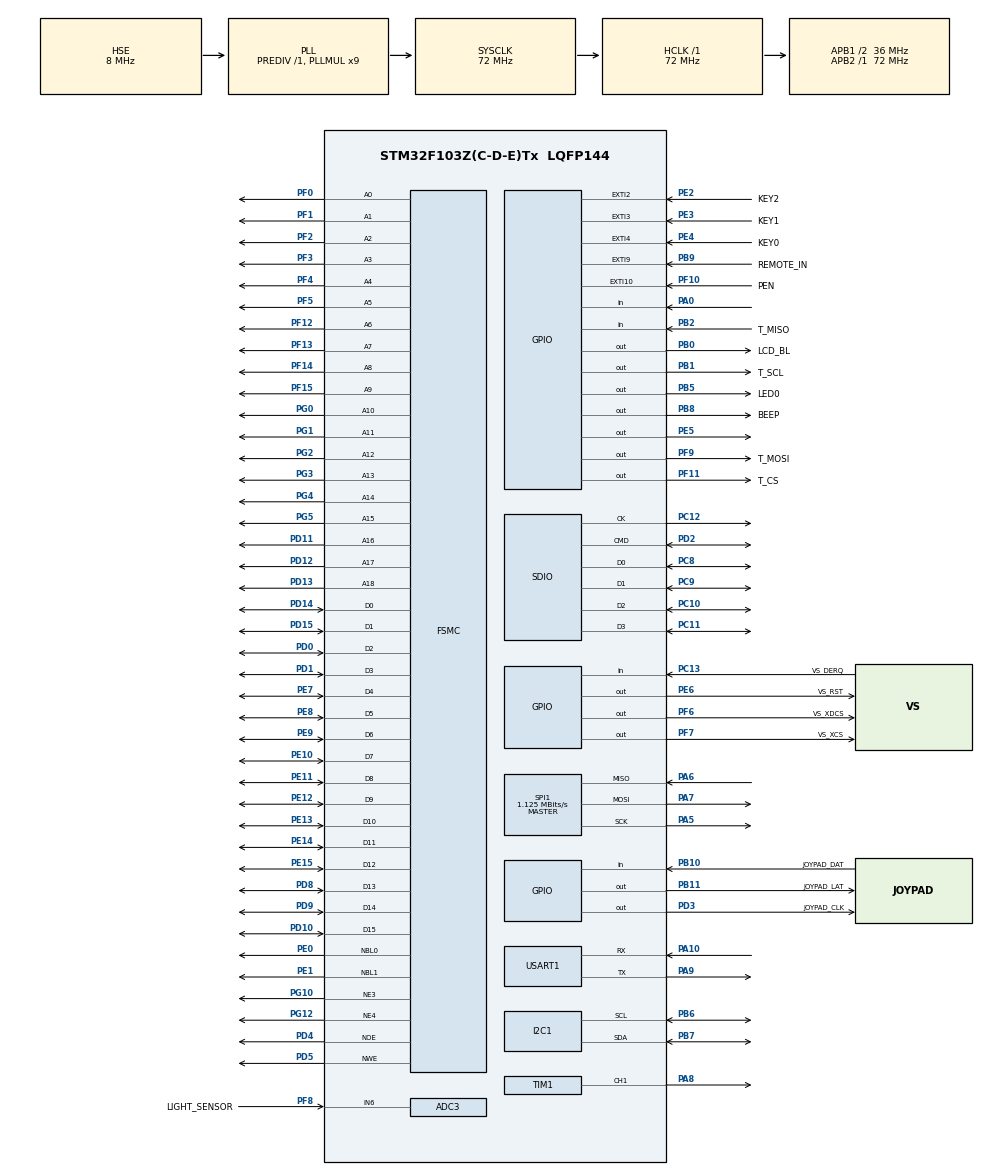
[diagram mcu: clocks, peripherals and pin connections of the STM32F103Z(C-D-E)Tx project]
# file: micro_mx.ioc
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ADC1.Channel-0\#ChannelRegularConversion=ADC_CHANNEL_TEMPSENSOR
ADC1.ContinuousConvMode=ENABLE
ADC1.NbrOfConversionFlag=1
ADC1.Rank-0\#ChannelRegularConversion=1
ADC1.SamplingTime-0\#ChannelRegularConversion=ADC_SAMPLETIME_1CYCLE_5
ADC1.master=1
ADC3.Channel-2\#ChannelRegularConversion=ADC_CHANNEL_6
ADC3.ContinuousConvMode=ENABLE
ADC3.NbrOfConversionFlag=1
ADC3.Rank-2\#ChannelRegularConversion=1
ADC3.SamplingTime-2\#ChannelRegularConversion=ADC_SAMPLETIME_1CYCLE_5
Dma.Request0=SDIO
Dma.SDIO.0.Direction=DMA_PERIPH_TO_MEMORY
Dma.SDIO.0.Instance=DMA2_Channel4
Dma.SDIO.0.MemDataAlignment=DMA_MDATAALIGN_WORD
Dma.SDIO.0.MemInc=DMA_MINC_ENABLE
Dma.SDIO.0.Mode=DMA_NORMAL
Dma.SDIO.0.PeriphDataAlignment=DMA_PDATAALIGN_WORD
Dma.SDIO.0.PeriphInc=DMA_PINC_DISABLE
Dma.SDIO.0.Priority=DMA_PRIORITY_LOW
FATFS.BSP.number=1
FATFS._FS_TINY=0
FATFS0.BSP.STBoard=false
FATFS0.BSP.api=Unknown
FATFS0.BSP.i2caddr=0
FATFS0.BSP.instance=PA0-WKUP
FATFS0.BSP.ip=GPIO
FATFS0.BSP.mode=Input
FATFS0.BSP.name=Detect_SDIO
FATFS0.BSP.solution=PA0-WKUP
FSMC.AddressSetupTime1=6
FSMC.AddressSetupTime2=4
FSMC.BusTurnAroundDuration1=0
FSMC.BusTurnAroundDuration2=0
FSMC.DataSetupTime1=26
FSMC.DataSetupTime2=4
FSMC.WriteOperation2=FSMC_WRITE_OPERATION_ENABLE
I2C1.I2C_Mode=I2C_Standard
Mcu.Family=STM32F1
Mcu.Name=STM32F103Z(C-D-E)Tx
Mcu.Package=LQFP144
NVIC.DMA2_Channel4_5_IRQn=true\:0\:0\:false\:false\:true\:false\:true\:true
NVIC.EXTI15_10_IRQn=true\:0\:0\:false\:false\:true\:true\:true\:true
NVIC.EXTI2_IRQn=true\:3\:0\:true\:false\:true\:true\:true\:true
NVIC.EXTI3_IRQn=true\:3\:0\:true\:false\:true\:true\:true\:true
NVIC.EXTI4_IRQn=true\:3\:0\:true\:false\:true\:true\:true\:true
NVIC.EXTI9_5_IRQn=true\:0\:0\:false\:false\:true\:true\:true\:true
NVIC.PriorityGroup=NVIC_PRIORITYGROUP_4
NVIC.SDIO_IRQn=true\:0\:0\:false\:false\:true\:true\:true\:true
NVIC.TIM2_IRQn=true\:0\:0\:false\:false\:true\:true\:true\:true
NVIC.USART1_IRQn=true\:0\:0\:false\:false\:true\:true\:true\:true
OSC_IN.Mode=HSE-External-Oscillator
OSC_IN.Signal=RCC_OSC_IN
OSC_OUT.Mode=HSE-External-Oscillator
OSC_OUT.Signal=RCC_OSC_OUT
PA0-WKUP.GPIO_PuPd=GPIO_PULLUP
PA0-WKUP.Signal=GPIO_Input
PA10.Mode=Asynchronous
PA10.Signal=USART1_RX
PA13.Mode=JTAG_5_pins
PA13.Signal=SYS_JTMS-SWDIO
PA14.Mode=JTAG_5_pins
PA14.Signal=SYS_JTCK-SWCLK
PA15.Mode=JTAG_5_pins
PA15.Signal=SYS_JTDI
PA5.Mode=Full_Duplex_Master
PA5.Signal=SPI1_SCK
PA6.Mode=Full_Duplex_Master
PA6.Signal=SPI1_MISO
PA7.Mode=Full_Duplex_Master
PA7.Signal=SPI1_MOSI
PA8.Signal=S_TIM1_CH1
PA9.Mode=Asynchronous
PA9.Signal=USART1_TX
PB0.GPIO_Label=LCD_BL
PB0.Signal=GPIO_Output
PB1.GPIO_Label=T_SCL
PB1.Signal=GPIO_Output
PB10.GPIO_Label=JOYPAD_DAT
PB10.Signal=GPIO_Input
PB11.GPIO_Label=JOYPAD_LAT
PB11.Signal=GPIO_Output
PB2.GPIO_Label=T_MISO
PB2.Signal=GPIO_Input
PB3.Mode=JTAG_5_pins
PB3.Signal=SYS_JTDO-TRACESWO
PB4.Mode=JTAG_5_pins
PB4.Signal=SYS_NJTRST
PB5.GPIO_Label=LED0
PB5.PinState=GPIO_PIN_SET
PB5.Signal=GPIO_Output
PB6.GPIO_Pu=GPIO_PULLUP
PB6.Mode=I2C
PB6.Signal=I2C1_SCL
PB7.GPIO_Pu=GPIO_PULLUP
PB7.Mode=I2C
PB7.Signal=I2C1_SDA
PB8.GPIO_Label=BEEP
PB8.Signal=GPIO_Output
PB9.GPIO_Label=REMOTE_IN
PB9.GPIO_ModeDefaultEXTI=GPIO_MODE_IT_FALLING
PB9.Signal=GPXTI9
PC10.Mode=SD_4_bits_Wide_bus
PC10.Signal=SDIO_D2
PC11.Mode=SD_4_bits_Wide_bus
PC11.Signal=SDIO_D3
PC12.Mode=SD_4_bits_Wide_bus
PC12.Signal=SDIO_CK
PC13-TAMPER-RTC.GPIO_Label=VS_DERQ
PC13-TAMPER-RTC.Signal=GPIO_Input
PC14-OSC32_IN.Mode=LSE-External-Oscillator
PC14-OSC32_IN.Signal=RCC_OSC32_IN
PC15-OSC32_OUT.Mode=LSE-External-Oscillator
PC15-OSC32_OUT.Signal=RCC_OSC32_OUT
PC8.Mode=SD_4_bits_Wide_bus
PC8.Signal=SDIO_D0
PC9.Mode=SD_4_bits_Wide_bus
PC9.Signal=SDIO_D1
PD0.Signal=FSMC_D2_DA2
PD1.Signal=FSMC_D3_DA3
PD10.Signal=FSMC_D15_DA15
PD11.Signal=FSMC_A16_CLE
PD12.Signal=FSMC_A17_ALE
PD13.Signal=FSMC_A18
PD14.Signal=FSMC_D0_DA0
PD15.Signal=FSMC_D1_DA1
PD2.Mode=SD_4_bits_Wide_bus
PD2.Signal=SDIO_CMD
PD3.GPIO_Label=JOYPAD_CLK
PD3.Signal=GPIO_Output
PD4.Signal=FSMC_NOE
PD5.Signal=FSMC_NWE
PD8.Signal=FSMC_D13_DA13
PD9.Signal=FSMC_D14_DA14
PE0.Signal=FSMC_NBL0
PE1.Signal=FSMC_NBL1
PE10.Signal=FSMC_D7_DA7
PE11.Signal=FSMC_D8_DA8
PE12.Signal=FSMC_D9_DA9
PE13.Signal=FSMC_D10_DA10
PE14.Signal=FSMC_D11_DA11
PE15.Signal=FSMC_D12_DA12
PE2.GPIO_Label=KEY2
PE2.GPIO_ModeDefaultEXTI=GPIO_MODE_IT_FALLING
PE2.GPIO_PuPd=GPIO_PULLUP
PE2.Signal=GPXTI2
PE3.GPIO_Label=KEY1
PE3.GPIO_ModeDefaultEXTI=GPIO_MODE_IT_FALLING
PE3.GPIO_PuPd=GPIO_PULLUP
PE3.Signal=GPXTI3
PE4.GPIO_Label=KEY0
PE4.GPIO_ModeDefaultEXTI=GPIO_MODE_IT_FALLING
PE4.GPIO_PuPd=GPIO_PULLUP
PE4.Signal=GPXTI4
PE5.Signal=GPIO_Output
PE6.GPIO_Label=VS_RST
PE6.Signal=GPIO_Output
PE7.Signal=FSMC_D4_DA4
PE8.Signal=FSMC_D5_DA5
PE9.Signal=FSMC_D6_DA6
PF0.Signal=FSMC_A0
PF1.Signal=FSMC_A1
PF10.GPIO_Label=PEN
PF10.GPIO_ModeDefaultEXTI=GPIO_MODE_IT_FALLING
PF10.Signal=GPXTI10
PF11.GPIO_Label=T_CS
PF11.PinState=GPIO_PIN_SET
PF11.Signal=GPIO_Output
PF12.Signal=FSMC_A6
PF13.Signal=FSMC_A7
PF14.Signal=FSMC_A8
PF15.Signal=FSMC_A9
PF2.Signal=FSMC_A2
PF3.Signal=FSMC_A3
PF4.Signal=FSMC_A4
PF5.Signal=FSMC_A5
PF6.GPIO_Label=VS_XDCS
PF6.Signal=GPIO_Output
PF7.GPIO_Label=VS_XCS
PF7.PinState=GPIO_PIN_SET
PF7.Signal=GPIO_Output
PF8.GPIO_Label=LIGHT_SENSOR
PF8.Signal=SharedAnalog_PF8
PF9.GPIO_Label=T_MOSI
PF9.Signal=GPIO_Output
PG0.Signal=FSMC_A10
PG1.Signal=FSMC_A11
PG10.Mode=NorPsramChipSelect3_2
PG10.Signal=FSMC_NE3
PG12.Mode=NorPsramChipSelect4_1
PG12.Signal=FSMC_NE4
PG2.Signal=FSMC_A12
PG3.Signal=FSMC_A13
PG4.Signal=FSMC_A14
PG5.Signal=FSMC_A15
ProjectManager.HeapSize=0x400
ProjectManager.StackSize=0x800
ProjectManager.TargetToolchain=STM32CubeIDE
RCC.ADCPresc=RCC_ADCPCLK2_DIV6
RCC.AHBFreq_Value=72000000
RCC.APB1CLKDivider=RCC_HCLK_DIV2
RCC.APB1Freq_Value=36000000
RCC.APB1TimFreq_Value=72000000
RCC.APB2Freq_Value=72000000
RCC.APB2TimFreq_Value=72000000
RCC.HCLKFreq_Value=72000000
RCC.PLLMUL=RCC_PLL_MUL9
RCC.PLLSourceVirtual=RCC_PLLSOURCE_HSE
RCC.RTCClockSelection=RCC_RTCCLKSOURCE_LSE
RCC.SYSCLKFreq_VALUE=72000000
RCC.SYSCLKSource=RCC_SYSCLKSOURCE_PLLCLK
RCC.USBFreq_Value=48000000
RCC.USBPrescaler=RCC_USBCLKSOURCE_PLL_DIV1_5
SDIO.ClockBypass=SDIO_CLOCK_BYPASS_DISABLE
SDIO.ClockDiv=10
SDIO.HardwareFlowControl=SDIO_HARDWARE_FLOW_CONTROL_DISABLE
SH.FSMC_A0.0=FSMC_A0,19b-a2
SH.FSMC_A1.0=FSMC_A1,19b-a2
SH.FSMC_A10.0=FSMC_A10,A10_1
SH.FSMC_A10.1=FSMC_A10,19b-a2
SH.FSMC_A11.0=FSMC_A11,19b-a2
SH.FSMC_A12.0=FSMC_A12,19b-a2
SH.FSMC_A13.0=FSMC_A13,19b-a2
SH.FSMC_A14.0=FSMC_A14,19b-a2
SH.FSMC_A15.0=FSMC_A15,19b-a2
SH.FSMC_A16_CLE.0=FSMC_A16,19b-a2
SH.FSMC_A17_ALE.0=FSMC_A17,19b-a2
SH.FSMC_A18.0=FSMC_A18,19b-a2
SH.FSMC_A2.0=FSMC_A2,19b-a2
SH.FSMC_A3.0=FSMC_A3,19b-a2
SH.FSMC_A4.0=FSMC_A4,19b-a2
SH.FSMC_A5.0=FSMC_A5,19b-a2
SH.FSMC_A6.0=FSMC_A6,19b-a2
SH.FSMC_A7.0=FSMC_A7,19b-a2
SH.FSMC_A8.0=FSMC_A8,19b-a2
SH.FSMC_A9.0=FSMC_A9,19b-a2
SH.FSMC_D0_DA0.0=FSMC_D0,16b-d1
SH.FSMC_D0_DA0.1=FSMC_D0,16b-d2
SH.FSMC_D10_DA10.0=FSMC_D10,16b-d1
SH.FSMC_D10_DA10.1=FSMC_D10,16b-d2
SH.FSMC_D11_DA11.0=FSMC_D11,16b-d1
SH.FSMC_D11_DA11.1=FSMC_D11,16b-d2
SH.FSMC_D12_DA12.0=FSMC_D12,16b-d1
SH.FSMC_D12_DA12.1=FSMC_D12,16b-d2
SH.FSMC_D13_DA13.0=FSMC_D13,16b-d1
SH.FSMC_D13_DA13.1=FSMC_D13,16b-d2
SH.FSMC_D14_DA14.0=FSMC_D14,16b-d1
SH.FSMC_D14_DA14.1=FSMC_D14,16b-d2
SH.FSMC_D15_DA15.0=FSMC_D15,16b-d1
SH.FSMC_D15_DA15.1=FSMC_D15,16b-d2
SH.FSMC_D1_DA1.0=FSMC_D1,16b-d1
SH.FSMC_D1_DA1.1=FSMC_D1,16b-d2
SH.FSMC_D2_DA2.0=FSMC_D2,16b-d1
SH.FSMC_D2_DA2.1=FSMC_D2,16b-d2
SH.FSMC_D3_DA3.0=FSMC_D3,16b-d1
SH.FSMC_D3_DA3.1=FSMC_D3,16b-d2
SH.FSMC_D4_DA4.0=FSMC_D4,16b-d1
SH.FSMC_D4_DA4.1=FSMC_D4,16b-d2
SH.FSMC_D5_DA5.0=FSMC_D5,16b-d1
SH.FSMC_D5_DA5.1=FSMC_D5,16b-d2
SH.FSMC_D6_DA6.0=FSMC_D6,16b-d1
SH.FSMC_D6_DA6.1=FSMC_D6,16b-d2
SH.FSMC_D7_DA7.0=FSMC_D7,16b-d1
SH.FSMC_D7_DA7.1=FSMC_D7,16b-d2
SH.FSMC_D8_DA8.0=FSMC_D8,16b-d1
SH.FSMC_D8_DA8.1=FSMC_D8,16b-d2
SH.FSMC_D9_DA9.0=FSMC_D9,16b-d1
SH.FSMC_D9_DA9.1=FSMC_D9,16b-d2
SH.FSMC_NBL0.0=FSMC_NBL0,2ByteEnable2
SH.FSMC_NBL1.0=FSMC_NBL1,2ByteEnable2
SH.FSMC_NOE.0=FSMC_NOE,Lcd1
SH.FSMC_NOE.1=FSMC_NOE,Sram2
SH.FSMC_NWE.0=FSMC_NWE,Lcd1
SH.FSMC_NWE.1=FSMC_NWE,Sram2
SH.S_TIM1_CH1.0=TIM1_CH1,PWM Generation1 CH1
SH.SharedAnalog_PF8.0=GPIO_Analog
SH.SharedAnalog_PF8.1=ADC3_IN6,IN6
SPI1.BaudRatePrescaler=SPI_BAUDRATEPRESCALER_64
SPI1.CalculateBaudRate=1.125 MBits/s
SPI1.Direction=SPI_DIRECTION_2LINES
SPI1.Mode=SPI_MODE_MASTER
SPI1.VirtualType=VM_MASTER
TIM1.Channel-PWM\ Generation1\ CH1=TIM_CHANNEL_1
TIM1.OCFastMode_PWM-PWM\ Generation1\ CH1=TIM_OCFAST_ENABLE
TIM1.Period=1000
TIM1.Pulse-PWM\ Generation1\ CH1=0
TIM2.Period=9999
TIM2.Prescaler=71
USART1.VirtualMode=VM_ASYNC
VP_ADC1_TempSens_Input.Mode=IN-TempSens
VP_FATFS_VS_SDIO.Mode=SDIO
VP_TIM1_VS_ClockSourceINT.Mode=Internal
VP_TIM2_VS_ClockSourceINT.Mode=Internal
board=custom

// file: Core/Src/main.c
/* USER CODE BEGIN Header */
/**
  ******************************************************************************
  * @file           : main.c
  * @brief          : Main program body
  ******************************************************************************
  * @attention
  *
  * <h2><center>&copy; Copyright (c) 2021 STMicroelectronics.
  * All rights reserved.</center></h2>
  *
  * This software component is licensed by ST under BSD 3-Clause license,
  * the "License"; You may not use this file except in compliance with the
  * License. You may obtain a copy of the License at:
  *                        opensource.org/licenses/BSD-3-Clause
  *
  ******************************************************************************
  */
/* USER CODE END Header */
#include "main.h"
#include "fatfs.h"

ADC_HandleTypeDef hadc1;
ADC_HandleTypeDef hadc3;

I2C_HandleTypeDef hi2c1;

SD_HandleTypeDef hsd;
DMA_HandleTypeDef hdma_sdio;

SPI_HandleTypeDef hspi1;

TIM_HandleTypeDef htim1;
TIM_HandleTypeDef htim2;

UART_HandleTypeDef huart1;

SRAM_HandleTypeDef hsram1;
SRAM_HandleTypeDef hsram2;

/* USER CODE BEGIN PV */
extern uint16_t xpos, ypos;
uint8_t touch_flag;

uint8_t joypad;

int p_x=0, p_y=0;
int p_prev_i, p_prev_j;
int p_curr_i, p_curr_j;
int p_d = 2;

int g1_x, g1_y;
int g1_prev_i, g1_prev_j;
int g1_curr_i, g1_curr_j;
int g1_d;
int g1_state;

int g2_x, g2_y;
int g2_prev_i, g2_prev_j;
int g2_curr_i, g2_curr_j;
int g2_d;
int g2_state;

int g3_x, g3_y;
int g3_prev_i, g3_prev_j;
int g3_curr_i, g3_curr_j;
int g3_d;
int g3_state;

int g4_x, g4_y;
int g4_prev_i, g4_prev_j;
int g4_curr_i, g4_curr_j;
int g4_d;
int g4_state;

// speed: To move 1 block, it needs speed cnt
int p_speed = 8;

int g1_speed = 64;
int g2_speed = 64;
int g3_speed = 64;
int g4_speed = 64;

// 0:main 1:name 2:play 3:gameover
int game_state = 2;

int score = 0;
int life = 3;
int level = 1;

int cnt = 0;
int level_start_cnt = 0;
// all food = 299
int food_cnt = 0;

// 1:block  10:food
int map_init_state[31][28] = {
		{ 1, 1, 1, 1, 1,  1, 1, 1, 1, 1,  1, 1, 1, 1, 1,  1, 1, 1, 1, 1,  1, 1, 1, 1, 1,  1, 1, 1},
		{ 1,10,10,10,10, 10,10,10,10,10, 10,10,10, 1, 1, 10,10,10,10,10, 10,10,10,10,10, 10,10, 1},
		{ 1,10, 1, 1, 1,  1,10, 1, 1, 1,  1, 1,10, 1, 1, 10, 1, 1, 1, 1,  1,10, 1, 1, 1,  1,10, 1},
		{ 1,10, 1, 1, 1,  1,10, 1, 1, 1,  1, 1,10, 1, 1, 10, 1, 1, 1, 1,  1,10, 1, 1, 1,  1,10, 1},
		{ 1,10, 1, 1, 1,  1,10, 1, 1, 1,  1, 1,10, 1, 1, 10, 1, 1, 1, 1,  1,10, 1, 1, 1,  1,10, 1},

		{ 1,10,10,10,10, 10,10,10,10,10, 10,10,10,10,10, 10,10,10,10,10, 10,10,10,10,10, 10,10, 1},
		{ 1,10, 1, 1, 1,  1,10, 1, 1,10,  1, 1, 1, 1, 1,  1, 1, 1,10, 1,  1,10, 1, 1, 1,  1,10, 1},
		{ 1,10, 1, 1, 1,  1,10, 1, 1,10,  1, 1, 1, 1, 1,  1, 1, 1,10, 1,  1,10, 1, 1, 1,  1,10, 1},
		{ 1,10,10,10,10, 10,10, 1, 1,10, 10,10,10, 1, 1, 10,10,10,10, 1,  1,10,10,10,10, 10,10, 1},
		{ 1, 1, 1, 1, 1,  1,10, 1, 1, 1,  1, 1,10, 1, 1, 10, 1, 1, 1, 1,  1,10, 1, 1, 1,  1, 1, 1},

		{ 0, 0, 0, 0, 0,  1,10, 1, 1, 1,  1, 1,10, 1, 1, 10, 1, 1, 1, 1,  1,10, 1, 0, 0,  0, 0, 0},
		{ 0, 0, 0, 0, 0,  1,10, 1, 1,10, 10,10,10,10,10, 10,10,10,10, 1,  1,10, 1, 0, 0,  0, 0, 0},
		{ 0, 0, 0, 0, 0,  1,10, 1, 1,10,  1, 1, 1, 1, 1,  1, 1, 1,10, 1,  1,10, 1, 0, 0,  0, 0, 0},
		{ 1, 1, 1, 1, 1,  1,10, 1, 1,10,  1, 0, 0, 0, 0,  0, 0, 1,10, 1,  1,10, 1, 1, 1,  1, 1, 1},
		{10,10,10,10,10, 10,10,10,10,10,  1, 0, 0, 0, 0,  0, 0, 1,10,10, 10,10,10,10,10, 10,10,10},

		{ 1, 1, 1, 1, 1,  1,10, 1, 1,10,  1, 0, 0, 0, 0,  0, 0, 1,10, 1,  1,10, 1, 1, 1,  1, 1, 1},
		{ 0, 0, 0, 0, 0,  1,10, 1, 1,10,  1, 1, 1, 1, 1,  1, 1, 1,10, 1,  1,10, 1, 0, 0,  0, 0, 0},
		{ 0, 0, 0, 0, 0,  1,10, 1, 1,10, 10,10,10, 0,10, 10,10,10,10, 1,  1,10, 1, 0, 0,  0, 0, 0},
		{ 0, 0, 0, 0, 0,  1,10, 1, 1,10,  1, 1, 1, 1, 1,  1, 1, 1,10, 1,  1,10, 1, 0, 0,  0, 0, 0},
		{ 1, 1, 1, 1, 1,  1,10, 1, 1,10,  1, 1, 1, 1, 1,  1, 1, 1,10, 1,  1,10, 1, 1, 1,  1, 1, 1},

		{ 1,10,10,10,10, 10,10,10,10,10, 10,10,10, 1, 1, 10,10,10,10,10, 10,10,10,10,10, 10,10, 1},
		{ 1,10, 1, 1, 1,  1,10, 1, 1, 1,  1, 1,10, 1, 1, 10, 1, 1, 1, 1,  1,10, 1, 1, 1,  1,10, 1},
		{ 1,10, 1, 1, 1,  1,10, 1, 1, 1,  1, 1,10, 1, 1, 10, 1, 1, 1, 1,  1,10, 1, 1, 1,  1,10, 1},
		{ 1,10,10,10, 1,  1,10,10,10,10, 10,10,10,10,10, 10,10,10,10,10, 10,10, 1, 1,10, 10,10, 1},
		{ 1, 1, 1,10, 1,  1,10, 1, 1,10,  1, 1, 1, 1, 1,  1, 1, 1,10, 1,  1,10, 1, 1,10,  1, 1, 1},

		{ 1, 1, 1,10, 1,  1,10, 1, 1,10,  1, 1, 1, 1, 1,  1, 1, 1,10, 1,  1,10, 1, 1,10,  1, 1, 1},
		{ 1,10,10,10,10, 10,10, 1, 1,10, 10,10,10, 1, 1, 10,10,10,10, 1,  1,10,10,10,10, 10,10, 1},
		{ 1,10, 1, 1, 1,  1, 1, 1, 1, 1,  1, 1,10, 1, 1, 10, 1, 1, 1, 1,  1, 1, 1, 1, 1,  1,10, 1},
		{ 1,10, 1, 1, 1,  1, 1, 1, 1, 1,  1, 1,10, 1, 1, 10, 1, 1, 1, 1,  1, 1, 1, 1, 1,  1,10, 1},
		{ 1,10,10,10,10, 10,10,10,10,10, 10,10,10,10,10, 10,10,10,10,10, 10,10,10,10,10, 10,10, 1},

		{ 1, 1, 1, 1, 1,  1, 1, 1, 1, 1,  1, 1, 1, 1, 1,  1, 1, 1, 1, 1,  1, 1, 1, 1, 1,  1, 1, 1}

};

int map[31][28];

/* USER CODE END PV */

void SystemClock_Config(void);
static void MX_GPIO_Init(void);
static void MX_DMA_Init(void);
static void MX_USART1_UART_Init(void);
static void MX_ADC1_Init(void);
static void MX_ADC3_Init(void);
static void MX_I2C1_Init(void);
static void MX_TIM1_Init(void);
static void MX_SPI1_Init(void);
static void MX_FSMC_Init(void);
static void MX_SDIO_SD_Init(void);
static void MX_TIM2_Init(void);
/* USER CODE BEGIN PFP */
void init_map(void);
int check_game_over(int p_temp_x, int p_temp_y, int g1_temp_x, int g1_temp_y, int g2_temp_x, int g2_temp_y, int g3_temp_x, int g3_temp_y, int g4_temp_x, int g4_temp_y);
int check_level_up(void);
/* USER CODE END PFP */

int main(void)
{
  /* USER CODE BEGIN 1 */
  int i, j;
  int p_temp_x, p_temp_y;
  int g1_temp_x, g1_temp_y;
  int g2_temp_x, g2_temp_y;
  int g3_temp_x, g3_temp_y;
  int g4_temp_x, g4_temp_y;
  int temp_score = 0;

  /* USER CODE END 1 */

  /* MCU Configuration--------------------------------------------------------*/

  /* Reset of all peripherals, Initializes the Flash interface and the Systick. */
  HAL_Init();

  /* Configure the system clock */
  SystemClock_Config();

  /* Initialize all configured peripherals */
  MX_GPIO_Init();
  MX_DMA_Init();
  MX_USART1_UART_Init();
  MX_ADC1_Init();
  MX_ADC3_Init();
  MX_I2C1_Init();
  MX_TIM1_Init();
  MX_SPI1_Init();
  MX_FSMC_Init();
  MX_SDIO_SD_Init();
  MX_FATFS_Init();
  MX_TIM2_Init();
  /* USER CODE BEGIN 2 */
  HAL_TIM_PWM_Start(&htim1, 0);
  Codex_HW_Reset();
  LCD_BL_on();

  LCD_init();
  LCD_Clear(COLOR_BLACK);
//  Codex_Speaker_on();

  HAL_Delay(100);

  HAL_TIM_Base_Start_IT(&htim2);

  init_map();
  temp_score = score;
  LCD_Draw_Score(temp_score, 1);
  LCD_Draw_Score(temp_score, 0);
  LCD_Draw_Level(level);

  /* USER CODE END 2 */

  /* Infinite loop */
  /* USER CODE BEGIN WHILE */
  while (1)
  {
	if(game_state == 2) {
		temp_score = score;
		p_temp_x = p_x, p_temp_y = p_y;
		g1_temp_x = g1_x, g1_temp_y = g1_y;
		g2_temp_x = g2_x, g2_temp_y = g2_y;
		g3_temp_x = g3_x, g3_temp_y = g3_y;
		g4_temp_x = g4_x, g4_temp_y = g4_y;

		if(map[g1_prev_i][g1_prev_j] != 0) {
			LCD_Draw_Food(8*g1_prev_j+8, 8*g1_prev_i+36);
		}
		LCD_Draw_Ghost(g1_temp_x, g1_temp_y, 1, 1);

		if(map[g2_prev_i][g2_prev_j] != 0) {
			LCD_Draw_Food(8*g2_prev_j+8, 8*g2_prev_i+36);
		}
		LCD_Draw_Ghost(g2_temp_x, g2_temp_y, 2, 1);

		if(map[g3_prev_i][g3_prev_j] != 0) {
			LCD_Draw_Food(8*g3_prev_j+8, 8*g3_prev_i+36);
		}
		LCD_Draw_Ghost(g3_temp_x, g3_temp_y, 3, 1);

		if(map[g4_prev_i][g4_prev_j] != 0) {
			LCD_Draw_Food(8*g4_prev_j+8, 8*g4_prev_i+36);
		}
		LCD_Draw_Ghost(g4_temp_x, g4_temp_y, 4, 1);

		LCD_Draw_Score(temp_score, 1);
		LCD_Draw_Pacman(p_temp_x, p_temp_y, 1);
		HAL_Delay(10);

		LCD_Draw_Score(temp_score, 0);
		LCD_Draw_Pacman(p_temp_x, p_temp_y, 0);

		LCD_Draw_Ghost(g1_temp_x, g1_temp_y, 1, 0);
		LCD_Draw_Ghost(g2_temp_x, g2_temp_y, 2, 0);
		LCD_Draw_Ghost(g3_temp_x, g3_temp_y, 3, 0);
		LCD_Draw_Ghost(g4_temp_x, g4_temp_y, 4, 0);

		if(check_game_over(p_temp_x, p_temp_y, g1_temp_x, g1_temp_y, g2_temp_x, g2_temp_y, g3_temp_x, g3_temp_y, g4_temp_x, g4_temp_y)) {
			if(life > 1) {
				life--;
				init_map();
			} else {
				game_state = 3;
			}
		}
		if(food_cnt > 296) {
			if(check_level_up()) {
				init_map();
				level++;
				g1_speed -= 8;
				g2_speed -= 8;
				g3_speed -= 8;
				g4_speed -= 8;
				LCD_Draw_Level(level);
			}
		}
		joypad = Joypad_read();
	} else if(game_state == 3) { // game over
		LCD_Clear(COLOR_BLACK);
		break;
	}

    /* USER CODE END WHILE */

    /* USER CODE BEGIN 3 */
  }
  LCD_Draw_Str(196, 120, "Your final score is", COLOR_WHITE, 1);
  LCD_Draw_Final_Score(score);
  while(1) {}
  /* USER CODE END 3 */
}

void SystemClock_Config(void)
{
  RCC_OscInitTypeDef RCC_OscInitStruct = {0};
  RCC_ClkInitTypeDef RCC_ClkInitStruct = {0};
  RCC_PeriphCLKInitTypeDef PeriphClkInit = {0};

  /** Initializes the RCC Oscillators according to the specified parameters
  * in the RCC_OscInitTypeDef structure.
  */
  RCC_OscInitStruct.OscillatorType = RCC_OSCILLATORTYPE_HSE;
  RCC_OscInitStruct.HSEState = RCC_HSE_ON;
  RCC_OscInitStruct.HSEPredivValue = RCC_HSE_PREDIV_DIV1;
  RCC_OscInitStruct.HSIState = RCC_HSI_ON;
  RCC_OscInitStruct.PLL.PLLState = RCC_PLL_ON;
  RCC_OscInitStruct.PLL.PLLSource = RCC_PLLSOURCE_HSE;
  RCC_OscInitStruct.PLL.PLLMUL = RCC_PLL_MUL9;
  if (HAL_RCC_OscConfig(&RCC_OscInitStruct) != HAL_OK)
  {
    Error_Handler();
  }

  /** Initializes the CPU, AHB and APB buses clocks
  */
  RCC_ClkInitStruct.ClockType = RCC_CLOCKTYPE_HCLK|RCC_CLOCKTYPE_SYSCLK
                              |RCC_CLOCKTYPE_PCLK1|RCC_CLOCKTYPE_PCLK2;
  RCC_ClkInitStruct.SYSCLKSource = RCC_SYSCLKSOURCE_PLLCLK;
  RCC_ClkInitStruct.AHBCLKDivider = RCC_SYSCLK_DIV1;
  RCC_ClkInitStruct.APB1CLKDivider = RCC_HCLK_DIV2;
  RCC_ClkInitStruct.APB2CLKDivider = RCC_HCLK_DIV1;

  if (HAL_RCC_ClockConfig(&RCC_ClkInitStruct, FLASH_LATENCY_2) != HAL_OK)
  {
    Error_Handler();
  }
  PeriphClkInit.PeriphClockSelection = RCC_PERIPHCLK_ADC;
  PeriphClkInit.AdcClockSelection = RCC_ADCPCLK2_DIV6;
  if (HAL_RCCEx_PeriphCLKConfig(&PeriphClkInit) != HAL_OK)
  {
    Error_Handler();
  }
}

static void MX_ADC1_Init(void)
{

  ADC_ChannelConfTypeDef sConfig = {0};

  /** Common config
  */
  hadc1.Instance = ADC1;
  hadc1.Init.ScanConvMode = ADC_SCAN_DISABLE;
  hadc1.Init.ContinuousConvMode = ENABLE;
  hadc1.Init.DiscontinuousConvMode = DISABLE;
  hadc1.Init.ExternalTrigConv = ADC_SOFTWARE_START;
  hadc1.Init.DataAlign = ADC_DATAALIGN_RIGHT;
  hadc1.Init.NbrOfConversion = 1;
  if (HAL_ADC_Init(&hadc1) != HAL_OK)
  {
    Error_Handler();
  }

  /** Configure Regular Channel
  */
  sConfig.Channel = ADC_CHANNEL_TEMPSENSOR;
  sConfig.Rank = ADC_REGULAR_RANK_1;
  sConfig.SamplingTime = ADC_SAMPLETIME_1CYCLE_5;
  if (HAL_ADC_ConfigChannel(&hadc1, &sConfig) != HAL_OK)
  {
    Error_Handler();
  }

}

static void MX_ADC3_Init(void)
{

  ADC_ChannelConfTypeDef sConfig = {0};

  /** Common config
  */
  hadc3.Instance = ADC3;
  hadc3.Init.ScanConvMode = ADC_SCAN_DISABLE;
  hadc3.Init.ContinuousConvMode = ENABLE;
  hadc3.Init.DiscontinuousConvMode = DISABLE;
  hadc3.Init.ExternalTrigConv = ADC_SOFTWARE_START;
  hadc3.Init.DataAlign = ADC_DATAALIGN_RIGHT;
  hadc3.Init.NbrOfConversion = 1;
  if (HAL_ADC_Init(&hadc3) != HAL_OK)
  {
    Error_Handler();
  }

  /** Configure Regular Channel
  */
  sConfig.Channel = ADC_CHANNEL_6;
  sConfig.Rank = ADC_REGULAR_RANK_1;
  sConfig.SamplingTime = ADC_SAMPLETIME_1CYCLE_5;
  if (HAL_ADC_ConfigChannel(&hadc3, &sConfig) != HAL_OK)
  {
    Error_Handler();
  }

}

static void MX_I2C1_Init(void)
{

  hi2c1.Instance = I2C1;
  hi2c1.Init.ClockSpeed = 100000;
  hi2c1.Init.DutyCycle = I2C_DUTYCYCLE_2;
  hi2c1.Init.OwnAddress1 = 0;
  hi2c1.Init.AddressingMode = I2C_ADDRESSINGMODE_7BIT;
  hi2c1.Init.DualAddressMode = I2C_DUALADDRESS_DISABLE;
  hi2c1.Init.OwnAddress2 = 0;
  hi2c1.Init.GeneralCallMode = I2C_GENERALCALL_DISABLE;
  hi2c1.Init.NoStretchMode = I2C_NOSTRETCH_DISABLE;
  if (HAL_I2C_Init(&hi2c1) != HAL_OK)
  {
    Error_Handler();
  }

}

static void MX_SDIO_SD_Init(void)
{

  hsd.Instance = SDIO;
  hsd.Init.ClockEdge = SDIO_CLOCK_EDGE_RISING;
  hsd.Init.ClockBypass = SDIO_CLOCK_BYPASS_DISABLE;
  hsd.Init.ClockPowerSave = SDIO_CLOCK_POWER_SAVE_DISABLE;
  hsd.Init.BusWide = SDIO_BUS_WIDE_1B;
  hsd.Init.HardwareFlowControl = SDIO_HARDWARE_FLOW_CONTROL_DISABLE;
  hsd.Init.ClockDiv = 10;
  /* USER CODE BEGIN SDIO_Init 2 */
  HAL_SD_Init(&hsd);
  HAL_SD_InitCard(&hsd);
  /* USER CODE END SDIO_Init 2 */

}

static void MX_SPI1_Init(void)
{

  /* SPI1 parameter configuration*/
  hspi1.Instance = SPI1;
  hspi1.Init.Mode = SPI_MODE_MASTER;
  hspi1.Init.Direction = SPI_DIRECTION_2LINES;
  hspi1.Init.DataSize = SPI_DATASIZE_8BIT;
  hspi1.Init.CLKPolarity = SPI_POLARITY_LOW;
  hspi1.Init.CLKPhase = SPI_PHASE_1EDGE;
  hspi1.Init.NSS = SPI_NSS_SOFT;
  hspi1.Init.BaudRatePrescaler = SPI_BAUDRATEPRESCALER_64;
  hspi1.Init.FirstBit = SPI_FIRSTBIT_MSB;
  hspi1.Init.TIMode = SPI_TIMODE_DISABLE;
  hspi1.Init.CRCCalculation = SPI_CRCCALCULATION_DISABLE;
  hspi1.Init.CRCPolynomial = 10;
  if (HAL_SPI_Init(&hspi1) != HAL_OK)
  {
    Error_Handler();
  }

}

static void MX_TIM1_Init(void)
{

  TIM_ClockConfigTypeDef sClockSourceConfig = {0};
  TIM_MasterConfigTypeDef sMasterConfig = {0};
  TIM_OC_InitTypeDef sConfigOC = {0};
  TIM_BreakDeadTimeConfigTypeDef sBreakDeadTimeConfig = {0};

  htim1.Instance = TIM1;
  htim1.Init.Prescaler = 0;
  htim1.Init.CounterMode = TIM_COUNTERMODE_UP;
  htim1.Init.Period = 1000;
  htim1.Init.ClockDivision = TIM_CLOCKDIVISION_DIV1;
  htim1.Init.RepetitionCounter = 0;
  htim1.Init.AutoReloadPreload = TIM_AUTORELOAD_PRELOAD_DISABLE;
  if (HAL_TIM_Base_Init(&htim1) != HAL_OK)
  {
    Error_Handler();
  }
  sClockSourceConfig.ClockSource = TIM_CLOCKSOURCE_INTERNAL;
  if (HAL_TIM_ConfigClockSource(&htim1, &sClockSourceConfig) != HAL_OK)
  {
    Error_Handler();
  }
  if (HAL_TIM_PWM_Init(&htim1) != HAL_OK)
  {
    Error_Handler();
  }
  sMasterConfig.MasterOutputTrigger = TIM_TRGO_RESET;
  sMasterConfig.MasterSlaveMode = TIM_MASTERSLAVEMODE_DISABLE;
  if (HAL_TIMEx_MasterConfigSynchronization(&htim1, &sMasterConfig) != HAL_OK)
  {
    Error_Handler();
  }
  sConfigOC.OCMode = TIM_OCMODE_PWM1;
  sConfigOC.Pulse = 0;
  sConfigOC.OCPolarity = TIM_OCPOLARITY_HIGH;
  sConfigOC.OCNPolarity = TIM_OCNPOLARITY_HIGH;
  sConfigOC.OCFastMode = TIM_OCFAST_ENABLE;
  sConfigOC.OCIdleState = TIM_OCIDLESTATE_RESET;
  sConfigOC.OCNIdleState = TIM_OCNIDLESTATE_RESET;
  if (HAL_TIM_PWM_ConfigChannel(&htim1, &sConfigOC, TIM_CHANNEL_1) != HAL_OK)
  {
    Error_Handler();
  }
  sBreakDeadTimeConfig.OffStateRunMode = TIM_OSSR_DISABLE;
  sBreakDeadTimeConfig.OffStateIDLEMode = TIM_OSSI_DISABLE;
  sBreakDeadTimeConfig.LockLevel = TIM_LOCKLEVEL_OFF;
  sBreakDeadTimeConfig.DeadTime = 0;
  sBreakDeadTimeConfig.BreakState = TIM_BREAK_DISABLE;
  sBreakDeadTimeConfig.BreakPolarity = TIM_BREAKPOLARITY_HIGH;
  sBreakDeadTimeConfig.AutomaticOutput = TIM_AUTOMATICOUTPUT_DISABLE;
  if (HAL_TIMEx_ConfigBreakDeadTime(&htim1, &sBreakDeadTimeConfig) != HAL_OK)
  {
    Error_Handler();
  }
  HAL_TIM_MspPostInit(&htim1);

}

static void MX_TIM2_Init(void)
{

  TIM_ClockConfigTypeDef sClockSourceConfig = {0};
  TIM_MasterConfigTypeDef sMasterConfig = {0};

  htim2.Instance = TIM2;
  htim2.Init.Prescaler = 71;
  htim2.Init.CounterMode = TIM_COUNTERMODE_UP;
  htim2.Init.Period = 9999;
  htim2.Init.ClockDivision = TIM_CLOCKDIVISION_DIV1;
  htim2.Init.AutoReloadPreload = TIM_AUTORELOAD_PRELOAD_DISABLE;
  if (HAL_TIM_Base_Init(&htim2) != HAL_OK)
  {
    Error_Handler();
  }
  sClockSourceConfig.ClockSource = TIM_CLOCKSOURCE_INTERNAL;
  if (HAL_TIM_ConfigClockSource(&htim2, &sClockSourceConfig) != HAL_OK)
  {
    Error_Handler();
  }
  sMasterConfig.MasterOutputTrigger = TIM_TRGO_RESET;
  sMasterConfig.MasterSlaveMode = TIM_MASTERSLAVEMODE_DISABLE;
  if (HAL_TIMEx_MasterConfigSynchronization(&htim2, &sMasterConfig) != HAL_OK)
  {
    Error_Handler();
  }

}

static void MX_USART1_UART_Init(void)
{

  huart1.Instance = USART1;
  huart1.Init.BaudRate = 115200;
  huart1.Init.WordLength = UART_WORDLENGTH_8B;
  huart1.Init.StopBits = UART_STOPBITS_1;
  huart1.Init.Parity = UART_PARITY_NONE;
  huart1.Init.Mode = UART_MODE_TX_RX;
  huart1.Init.HwFlowCtl = UART_HWCONTROL_NONE;
  huart1.Init.OverSampling = UART_OVERSAMPLING_16;
  if (HAL_UART_Init(&huart1) != HAL_OK)
  {
    Error_Handler();
  }

}

static void MX_DMA_Init(void)
{

  /* DMA controller clock enable */
  __HAL_RCC_DMA2_CLK_ENABLE();

  /* DMA interrupt init */
  /* DMA2_Channel4_5_IRQn interrupt configuration */
  HAL_NVIC_SetPriority(DMA2_Channel4_5_IRQn, 0, 0);
  HAL_NVIC_EnableIRQ(DMA2_Channel4_5_IRQn);

}

static void MX_GPIO_Init(void)
{
  GPIO_InitTypeDef GPIO_InitStruct = {0};

  /* GPIO Ports Clock Enable */
  __HAL_RCC_GPIOE_CLK_ENABLE();
  __HAL_RCC_GPIOC_CLK_ENABLE();
  __HAL_RCC_GPIOF_CLK_ENABLE();
  __HAL_RCC_GPIOA_CLK_ENABLE();
  __HAL_RCC_GPIOB_CLK_ENABLE();
  __HAL_RCC_GPIOG_CLK_ENABLE();
  __HAL_RCC_GPIOD_CLK_ENABLE();

  /*Configure GPIO pin Output Level */
  HAL_GPIO_WritePin(GPIOE, GPIO_PIN_5|VS_RST_Pin, GPIO_PIN_RESET);

  /*Configure GPIO pin Output Level */
  HAL_GPIO_WritePin(GPIOF, VS_XDCS_Pin|T_MOSI_Pin, GPIO_PIN_RESET);

  /*Configure GPIO pin Output Level */
  HAL_GPIO_WritePin(GPIOF, VS_XCS_Pin|T_CS_Pin, GPIO_PIN_SET);

  /*Configure GPIO pin Output Level */
  HAL_GPIO_WritePin(GPIOB, LCD_BL_Pin|T_SCL_Pin|JOYPAD_LAT_Pin|BEEP_Pin, GPIO_PIN_RESET);

  /*Configure GPIO pin Output Level */
  HAL_GPIO_WritePin(JOYPAD_CLK_GPIO_Port, JOYPAD_CLK_Pin, GPIO_PIN_RESET);

  /*Configure GPIO pin Output Level */
  HAL_GPIO_WritePin(LED0_GPIO_Port, LED0_Pin, GPIO_PIN_SET);

  /*Configure GPIO pins : KEY2_Pin KEY1_Pin KEY0_Pin */
  GPIO_InitStruct.Pin = KEY2_Pin|KEY1_Pin|KEY0_Pin;
  GPIO_InitStruct.Mode = GPIO_MODE_IT_FALLING;
  GPIO_InitStruct.Pull = GPIO_PULLUP;
  HAL_GPIO_Init(GPIOE, &GPIO_InitStruct);

  /*Configure GPIO pins : PE5 VS_RST_Pin */
  GPIO_InitStruct.Pin = GPIO_PIN_5|VS_RST_Pin;
  GPIO_InitStruct.Mode = GPIO_MODE_OUTPUT_PP;
  GPIO_InitStruct.Pull = GPIO_NOPULL;
  GPIO_InitStruct.Speed = GPIO_SPEED_FREQ_LOW;
  HAL_GPIO_Init(GPIOE, &GPIO_InitStruct);

  /*Configure GPIO pin : VS_DERQ_Pin */
  GPIO_InitStruct.Pin = VS_DERQ_Pin;
  GPIO_InitStruct.Mode = GPIO_MODE_INPUT;
  GPIO_InitStruct.Pull = GPIO_NOPULL;
  HAL_GPIO_Init(VS_DERQ_GPIO_Port, &GPIO_InitStruct);

  /*Configure GPIO pins : VS_XDCS_Pin VS_XCS_Pin T_MOSI_Pin T_CS_Pin */
  GPIO_InitStruct.Pin = VS_XDCS_Pin|VS_XCS_Pin|T_MOSI_Pin|T_CS_Pin;
  GPIO_InitStruct.Mode = GPIO_MODE_OUTPUT_PP;
  GPIO_InitStruct.Pull = GPIO_NOPULL;
  GPIO_InitStruct.Speed = GPIO_SPEED_FREQ_LOW;
  HAL_GPIO_Init(GPIOF, &GPIO_InitStruct);

  /*Configure GPIO pin : PEN_Pin */
  GPIO_InitStruct.Pin = PEN_Pin;
  GPIO_InitStruct.Mode = GPIO_MODE_IT_FALLING;
  GPIO_InitStruct.Pull = GPIO_NOPULL;
  HAL_GPIO_Init(PEN_GPIO_Port, &GPIO_InitStruct);

  /*Configure GPIO pin : PA0 */
  GPIO_InitStruct.Pin = GPIO_PIN_0;
  GPIO_InitStruct.Mode = GPIO_MODE_INPUT;
  GPIO_InitStruct.Pull = GPIO_PULLUP;
  HAL_GPIO_Init(GPIOA, &GPIO_InitStruct);

  /*Configure GPIO pins : LCD_BL_Pin T_SCL_Pin JOYPAD_LAT_Pin LED0_Pin
                           BEEP_Pin */
  GPIO_InitStruct.Pin = LCD_BL_Pin|T_SCL_Pin|JOYPAD_LAT_Pin|LED0_Pin
                          |BEEP_Pin;
  GPIO_InitStruct.Mode = GPIO_MODE_OUTPUT_PP;
  GPIO_InitStruct.Pull = GPIO_NOPULL;
  GPIO_InitStruct.Speed = GPIO_SPEED_FREQ_LOW;
  HAL_GPIO_Init(GPIOB, &GPIO_InitStruct);

  /*Configure GPIO pins : T_MISO_Pin JOYPAD_DAT_Pin */
  GPIO_InitStruct.Pin = T_MISO_Pin|JOYPAD_DAT_Pin;
  GPIO_InitStruct.Mode = GPIO_MODE_INPUT;
  GPIO_InitStruct.Pull = GPIO_NOPULL;
  HAL_GPIO_Init(GPIOB, &GPIO_InitStruct);

  /*Configure GPIO pin : JOYPAD_CLK_Pin */
  GPIO_InitStruct.Pin = JOYPAD_CLK_Pin;
  GPIO_InitStruct.Mode = GPIO_MODE_OUTPUT_PP;
  GPIO_InitStruct.Pull = GPIO_NOPULL;
  GPIO_InitStruct.Speed = GPIO_SPEED_FREQ_LOW;
  HAL_GPIO_Init(JOYPAD_CLK_GPIO_Port, &GPIO_InitStruct);

  /*Configure GPIO pin : REMOTE_IN_Pin */
  GPIO_InitStruct.Pin = REMOTE_IN_Pin;
  GPIO_InitStruct.Mode = GPIO_MODE_IT_FALLING;
  GPIO_InitStruct.Pull = GPIO_NOPULL;
  HAL_GPIO_Init(REMOTE_IN_GPIO_Port, &GPIO_InitStruct);

  /* EXTI interrupt init*/
  HAL_NVIC_SetPriority(EXTI2_IRQn, 3, 0);
  HAL_NVIC_EnableIRQ(EXTI2_IRQn);

  HAL_NVIC_SetPriority(EXTI3_IRQn, 3, 0);
  HAL_NVIC_EnableIRQ(EXTI3_IRQn);

  HAL_NVIC_SetPriority(EXTI4_IRQn, 3, 0);
  HAL_NVIC_EnableIRQ(EXTI4_IRQn);

  HAL_NVIC_SetPriority(EXTI9_5_IRQn, 0, 0);
  HAL_NVIC_EnableIRQ(EXTI9_5_IRQn);

  HAL_NVIC_SetPriority(EXTI15_10_IRQn, 0, 0);
  HAL_NVIC_EnableIRQ(EXTI15_10_IRQn);

}

/* FSMC initialization function */
static void MX_FSMC_Init(void)
{

  FSMC_NORSRAM_TimingTypeDef Timing = {0};

  /** Perform the SRAM1 memory initialization sequence
  */
  hsram1.Instance = FSMC_NORSRAM_DEVICE;
  hsram1.Extended = FSMC_NORSRAM_EXTENDED_DEVICE;
  /* hsram1.Init */
  hsram1.Init.NSBank = FSMC_NORSRAM_BANK4;
  hsram1.Init.DataAddressMux = FSMC_DATA_ADDRESS_MUX_DISABLE;
  hsram1.Init.MemoryType = FSMC_MEMORY_TYPE_SRAM;
  hsram1.Init.MemoryDataWidth = FSMC_NORSRAM_MEM_BUS_WIDTH_16;
  hsram1.Init.BurstAccessMode = FSMC_BURST_ACCESS_MODE_DISABLE;
  hsram1.Init.WaitSignalPolarity = FSMC_WAIT_SIGNAL_POLARITY_LOW;
  hsram1.Init.WrapMode = FSMC_WRAP_MODE_DISABLE;
  hsram1.Init.WaitSignalActive = FSMC_WAIT_TIMING_BEFORE_WS;
  hsram1.Init.WriteOperation = FSMC_WRITE_OPERATION_ENABLE;
  hsram1.Init.WaitSignal = FSMC_WAIT_SIGNAL_DISABLE;
  hsram1.Init.ExtendedMode = FSMC_EXTENDED_MODE_DISABLE;
  hsram1.Init.AsynchronousWait = FSMC_ASYNCHRONOUS_WAIT_DISABLE;
  hsram1.Init.WriteBurst = FSMC_WRITE_BURST_DISABLE;
  /* Timing */
  Timing.AddressSetupTime = 6;
  Timing.AddressHoldTime = 15;
  Timing.DataSetupTime = 26;
  Timing.BusTurnAroundDuration = 0;
  Timing.CLKDivision = 16;
  Timing.DataLatency = 17;
  Timing.AccessMode = FSMC_ACCESS_MODE_A;
  /* ExtTiming */

  if (HAL_SRAM_Init(&hsram1, &Timing, NULL) != HAL_OK)
  {
    Error_Handler( );
  }

  /** Perform the SRAM2 memory initialization sequence
  */
  hsram2.Instance = FSMC_NORSRAM_DEVICE;
  hsram2.Extended = FSMC_NORSRAM_EXTENDED_DEVICE;
  /* hsram2.Init */
  hsram2.Init.NSBank = FSMC_NORSRAM_BANK3;
  hsram2.Init.DataAddressMux = FSMC_DATA_ADDRESS_MUX_DISABLE;
  hsram2.Init.MemoryType = FSMC_MEMORY_TYPE_SRAM;
  hsram2.Init.MemoryDataWidth = FSMC_NORSRAM_MEM_BUS_WIDTH_16;
  hsram2.Init.BurstAccessMode = FSMC_BURST_ACCESS_MODE_DISABLE;
  hsram2.Init.WaitSignalPolarity = FSMC_WAIT_SIGNAL_POLARITY_LOW;
  hsram2.Init.WrapMode = FSMC_WRAP_MODE_DISABLE;
  hsram2.Init.WaitSignalActive = FSMC_WAIT_TIMING_BEFORE_WS;
  hsram2.Init.WriteOperation = FSMC_WRITE_OPERATION_ENABLE;
  hsram2.Init.WaitSignal = FSMC_WAIT_SIGNAL_DISABLE;
  hsram2.Init.ExtendedMode = FSMC_EXTENDED_MODE_DISABLE;
  hsram2.Init.AsynchronousWait = FSMC_ASYNCHRONOUS_WAIT_DISABLE;
  hsram2.Init.WriteBurst = FSMC_WRITE_BURST_DISABLE;
  /* Timing */
  Timing.AddressSetupTime = 4;
  Timing.AddressHoldTime = 15;
  Timing.DataSetupTime = 4;
  Timing.BusTurnAroundDuration = 0;
  Timing.CLKDivision = 16;
  Timing.DataLatency = 17;
  Timing.AccessMode = FSMC_ACCESS_MODE_A;
  /* ExtTiming */

  if (HAL_SRAM_Init(&hsram2, &Timing, NULL) != HAL_OK)
  {
    Error_Handler( );
  }

  /** Disconnect NADV
  */

  __HAL_AFIO_FSMCNADV_DISCONNECTED();

}

/* USER CODE BEGIN 4 */

void init_map() {
	int i, j;
	food_cnt = 0;
	level_start_cnt = cnt;
	p_prev_i=17, p_prev_j=13;
	p_curr_i=17, p_curr_j=13;
	p_d = 2;
	p_x = 12 + (p_prev_j * 8);
	p_y = 40 + (p_prev_i * 8);

	g1_prev_i=11, g1_prev_j=14;
	g1_curr_i=11, g1_curr_j=14;
	g1_d = 0;
	g1_x = 12 + (g1_prev_j * 8);
	g1_y = 40 + (g1_prev_i * 8);
	g1_state = 1;

	g2_prev_i=13, g2_prev_j=14;
	g2_curr_i=13, g2_curr_j=14;
	g2_d = 3;
	g2_x = 12 + (g2_prev_j * 8);
	g2_y = 40 + (g2_prev_i * 8);
	g2_state = 0;

	g3_prev_i=15, g3_prev_j=16;
	g3_curr_i=15, g3_curr_j=16;
	g3_d = 1;
	g3_x = 12 + (g3_prev_j * 8);
	g3_y = 40 + (g3_prev_i * 8);
	g3_state = 0;

	g4_prev_i=15, g4_prev_j=12;
	g4_curr_i=15, g4_curr_j=12;
	g4_d = 1;
	g4_x = 12 + (g4_prev_j * 8);
	g4_y = 40 + (g4_prev_i * 8);
	g4_state = 0;

	for(i=0; i<31; i++) {
		for(j=0; j<28; j++) {
			map[i][j] = map_init_state[i][j];
			if(map_init_state[i][j] == 1) {
				LCD_Draw_Block(8*j+8, 8*i+36);
			} else if(map_init_state[i][j] == 10) {
				LCD_Draw_Food(8*j+8, 8*i+36);
			}
		}
	}
	LCD_Draw_Life(life+1, 0);
	LCD_Draw_Life(life, 1);
}

int check_game_over(int p_temp_x, int p_temp_y, int g1_temp_x, int g1_temp_y, int g2_temp_x, int g2_temp_y, int g3_temp_x, int g3_temp_y, int g4_temp_x, int g4_temp_y) {
	if((g1_temp_x + 8 > p_temp_x) && (g1_temp_x - 8 < p_temp_x) && (g1_temp_y + 8 > p_temp_y) && (g1_temp_y - 8 < p_temp_y)) {
		return 1;
	}
	if((g2_temp_x + 8 > p_temp_x) && (g2_temp_x - 8 < p_temp_x) && (g2_temp_y + 8 > p_temp_y) && (g2_temp_y - 8 < p_temp_y)) {
		return 1;
	}
	if((g3_temp_x + 8 > p_temp_x) && (g3_temp_x - 8 < p_temp_x) && (g3_temp_y + 8 > p_temp_y) && (g3_temp_y - 8 < p_temp_y)) {
		return 1;
	}
	if((g4_temp_x + 8 > p_temp_x) && (g4_temp_x - 8 < p_temp_x) && (g4_temp_y + 8 > p_temp_y) && (g4_temp_y - 8 < p_temp_y)) {
		return 1;
	}
	return 0;
}

int check_level_up() {
	int i, j;
	for(i=0; i<31; i++) {
		for(j=0; j<28; j++) {
			if(map[i][j] == 10 || map[i][j] == 50) {
				return 0;
			}
		}
	}
	return 1;
}

/* USER CODE END 4 */

void Error_Handler(void)
{
  __disable_irq();
  while (1)
  {
  }
}
